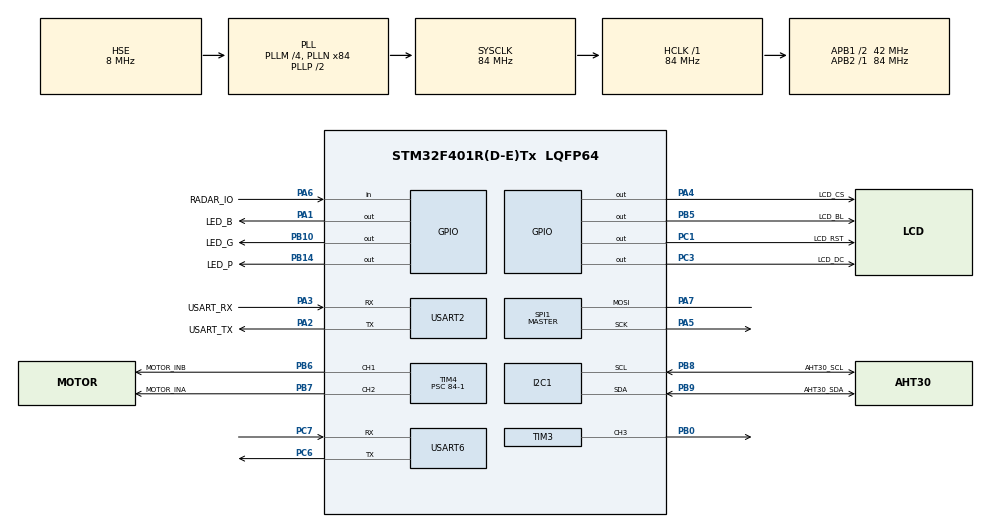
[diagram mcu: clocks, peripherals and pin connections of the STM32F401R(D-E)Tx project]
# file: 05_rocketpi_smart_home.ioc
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Dma.Request0=USART6_RX
Dma.Request1=USART6_TX
Dma.Request2=SPI1_TX
Dma.Request3=USART2_RX
Dma.Request4=USART2_TX
Dma.SPI1_TX.2.Direction=DMA_MEMORY_TO_PERIPH
Dma.SPI1_TX.2.FIFOMode=DMA_FIFOMODE_DISABLE
Dma.SPI1_TX.2.Instance=DMA2_Stream3
Dma.SPI1_TX.2.MemDataAlignment=DMA_MDATAALIGN_BYTE
Dma.SPI1_TX.2.MemInc=DMA_MINC_ENABLE
Dma.SPI1_TX.2.Mode=DMA_NORMAL
Dma.SPI1_TX.2.PeriphDataAlignment=DMA_PDATAALIGN_BYTE
Dma.SPI1_TX.2.PeriphInc=DMA_PINC_DISABLE
Dma.SPI1_TX.2.Priority=DMA_PRIORITY_LOW
Dma.USART2_RX.3.Direction=DMA_PERIPH_TO_MEMORY
Dma.USART2_RX.3.FIFOMode=DMA_FIFOMODE_DISABLE
Dma.USART2_RX.3.Instance=DMA1_Stream5
Dma.USART2_RX.3.MemDataAlignment=DMA_MDATAALIGN_BYTE
Dma.USART2_RX.3.MemInc=DMA_MINC_ENABLE
Dma.USART2_RX.3.Mode=DMA_NORMAL
Dma.USART2_RX.3.PeriphDataAlignment=DMA_PDATAALIGN_BYTE
Dma.USART2_RX.3.PeriphInc=DMA_PINC_DISABLE
Dma.USART2_RX.3.Priority=DMA_PRIORITY_LOW
Dma.USART2_TX.4.Direction=DMA_MEMORY_TO_PERIPH
Dma.USART2_TX.4.FIFOMode=DMA_FIFOMODE_DISABLE
Dma.USART2_TX.4.Instance=DMA1_Stream6
Dma.USART2_TX.4.MemDataAlignment=DMA_MDATAALIGN_BYTE
Dma.USART2_TX.4.MemInc=DMA_MINC_ENABLE
Dma.USART2_TX.4.Mode=DMA_NORMAL
Dma.USART2_TX.4.PeriphDataAlignment=DMA_PDATAALIGN_BYTE
Dma.USART2_TX.4.PeriphInc=DMA_PINC_DISABLE
Dma.USART2_TX.4.Priority=DMA_PRIORITY_LOW
Dma.USART6_RX.0.Direction=DMA_PERIPH_TO_MEMORY
Dma.USART6_RX.0.FIFOMode=DMA_FIFOMODE_DISABLE
Dma.USART6_RX.0.Instance=DMA2_Stream1
Dma.USART6_RX.0.MemDataAlignment=DMA_MDATAALIGN_BYTE
Dma.USART6_RX.0.MemInc=DMA_MINC_ENABLE
Dma.USART6_RX.0.Mode=DMA_NORMAL
Dma.USART6_RX.0.PeriphDataAlignment=DMA_PDATAALIGN_BYTE
Dma.USART6_RX.0.PeriphInc=DMA_PINC_DISABLE
Dma.USART6_RX.0.Priority=DMA_PRIORITY_LOW
Dma.USART6_TX.1.Direction=DMA_MEMORY_TO_PERIPH
Dma.USART6_TX.1.FIFOMode=DMA_FIFOMODE_DISABLE
Dma.USART6_TX.1.Instance=DMA2_Stream6
Dma.USART6_TX.1.MemDataAlignment=DMA_MDATAALIGN_BYTE
Dma.USART6_TX.1.MemInc=DMA_MINC_ENABLE
Dma.USART6_TX.1.Mode=DMA_NORMAL
Dma.USART6_TX.1.PeriphDataAlignment=DMA_PDATAALIGN_BYTE
Dma.USART6_TX.1.PeriphInc=DMA_PINC_DISABLE
Dma.USART6_TX.1.Priority=DMA_PRIORITY_LOW
Mcu.Family=STM32F4
Mcu.Name=STM32F401R(D-E)Tx
Mcu.Package=LQFP64
NVIC.DMA1_Stream5_IRQn=true\:0\:0\:false\:false\:true\:false\:true\:true
NVIC.DMA1_Stream6_IRQn=true\:0\:0\:false\:false\:true\:false\:true\:true
NVIC.DMA2_Stream1_IRQn=true\:0\:0\:false\:false\:true\:false\:true\:true
NVIC.DMA2_Stream3_IRQn=true\:0\:0\:false\:false\:true\:false\:true\:true
NVIC.DMA2_Stream6_IRQn=true\:0\:0\:false\:false\:true\:false\:true\:true
NVIC.PriorityGroup=NVIC_PRIORITYGROUP_4
NVIC.SPI1_IRQn=true\:0\:0\:false\:false\:true\:true\:true\:true
NVIC.USART2_IRQn=true\:0\:0\:false\:false\:true\:true\:true\:true
NVIC.USART6_IRQn=true\:0\:0\:false\:false\:true\:true\:true\:true
PA1.GPIO_Label=LED_B
PA1.Signal=GPIO_Output
PA13.GPIO_Label=TMS
PA13.Mode=Serial_Wire
PA13.Signal=SYS_JTMS-SWDIO
PA14.GPIO_Label=TCK
PA14.Mode=Serial_Wire
PA14.Signal=SYS_JTCK-SWCLK
PA2.GPIO_Label=USART_TX
PA2.GPIO_Mode=GPIO_MODE_AF_PP
PA2.GPIO_PuPd=GPIO_NOPULL
PA2.GPIO_Speed=GPIO_SPEED_FREQ_LOW
PA2.Mode=Asynchronous
PA2.Signal=USART2_TX
PA3.GPIO_Label=USART_RX
PA3.GPIO_Mode=GPIO_MODE_AF_PP
PA3.GPIO_PuPd=GPIO_NOPULL
PA3.GPIO_Speed=GPIO_SPEED_FREQ_LOW
PA3.Mode=Asynchronous
PA3.Signal=USART2_RX
PA4.GPIO_Label=LCD_CS
PA4.GPIO_Speed=GPIO_SPEED_FREQ_LOW
PA4.Signal=GPIO_Output
PA5.Mode=Simplex_Bidirectional_Master
PA5.Signal=SPI1_SCK
PA6.GPIO_Label=RADAR_IO
PA6.Signal=GPIO_Input
PA7.Mode=Simplex_Bidirectional_Master
PA7.Signal=SPI1_MOSI
PB0.Signal=S_TIM3_CH3
PB10.GPIO_Label=LED_G
PB10.Signal=GPIO_Output
PB14.GPIO_Label=LED_P
PB14.Signal=GPIO_Output
PB5.GPIO_Label=LCD_BL
PB5.Signal=GPIO_Output
PB6.GPIO_Label=MOTOR_INB
PB6.Signal=S_TIM4_CH1
PB7.GPIO_Label=MOTOR_INA
PB7.Signal=S_TIM4_CH2
PB8.GPIO_Label=AHT30_SCL
PB8.Mode=I2C
PB8.Signal=I2C1_SCL
PB9.GPIO_Label=AHT30_SDA
PB9.Mode=I2C
PB9.Signal=I2C1_SDA
PC1.GPIO_Label=LCD_RST
PC1.Signal=GPIO_Output
PC3.GPIO_Label=LCD_DC
PC3.Signal=GPIO_Output
PC6.Mode=Asynchronous
PC6.Signal=USART6_TX
PC7.Mode=Asynchronous
PC7.Signal=USART6_RX
PH0\ -\ OSC_IN.Mode=HSE-External-Oscillator
PH0\ -\ OSC_IN.Signal=RCC_OSC_IN
PH1\ -\ OSC_OUT.Mode=HSE-External-Oscillator
PH1\ -\ OSC_OUT.Signal=RCC_OSC_OUT
ProjectManager.HeapSize=0x4000
ProjectManager.StackSize=0x1000
ProjectManager.TargetToolchain=MDK-ARM V5.27
RCC.48MHZClocksFreq_Value=24000000
RCC.AHBFreq_Value=84000000
RCC.APB1CLKDivider=RCC_HCLK_DIV2
RCC.APB1Freq_Value=42000000
RCC.APB1TimFreq_Value=84000000
RCC.APB2Freq_Value=84000000
RCC.APB2TimFreq_Value=84000000
RCC.CortexFreq_Value=84000000
RCC.HCLKFreq_Value=84000000
RCC.HSE_VALUE=8000000
RCC.HSI_VALUE=16000000
RCC.LSE_VALUE=32768
RCC.PLLM=4
RCC.PLLN=84
RCC.PLLQ=7
RCC.PLLSourceVirtual=RCC_PLLSOURCE_HSE
RCC.SYSCLKFreq_VALUE=84000000
RCC.SYSCLKSource=RCC_SYSCLKSOURCE_PLLCLK
RCC.VCOOutputFreq_Value=168000000
SH.S_TIM3_CH3.0=TIM3_CH3,PWM Generation3 CH3
SH.S_TIM4_CH1.0=TIM4_CH1,PWM Generation1 CH1
SH.S_TIM4_CH2.0=TIM4_CH2,PWM Generation2 CH2
SPI1.Direction=SPI_DIRECTION_1LINE
SPI1.Mode=SPI_MODE_MASTER
SPI1.VirtualType=VM_MASTER
TIM3.Channel-PWM\ Generation3\ CH3=TIM_CHANNEL_3
TIM3.Period=369
TIM3.Prescaler=84-1
TIM3.Pulse-PWM\ Generation3\ CH3=185
TIM4.Channel-PWM\ Generation1\ CH1=TIM_CHANNEL_1
TIM4.Channel-PWM\ Generation2\ CH2=TIM_CHANNEL_2
TIM4.Period=50-1
TIM4.Prescaler=84-1
USART2.VirtualMode=VM_ASYNC
USART6.VirtualMode=VM_ASYNC
board=NUCLEO-F401RE

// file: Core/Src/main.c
/* USER CODE BEGIN Header */
/**
  ******************************************************************************
  * @file           : main.c
  * @brief          : Main program body
  ******************************************************************************
  * @attention
  *
  * Copyright (c) 2025 STMicroelectronics.
  * All rights reserved.
  *
  * This software is licensed under terms that can be found in the LICENSE file
  * in the root directory of this software component.
  * If no LICENSE file comes with this software, it is provided AS-IS.
  *
  ******************************************************************************
  */
/* USER CODE END Header */
#include "main.h"
#include "dma.h"
#include "i2c.h"
#include "spi.h"
#include "tim.h"
#include "usart.h"
#include "gpio.h"

/* USER CODE BEGIN Includes */
#include "app.h"
#include <stdio.h>
#include "font16x24_ascii.h"
/* USER CODE END Includes */

void SystemClock_Config(void);

int main(void)
{

  /* MCU Configuration--------------------------------------------------------*/

  /* Reset of all peripherals, Initializes the Flash interface and the Systick. */
  HAL_Init();

  /* Configure the system clock */
  SystemClock_Config();

  /* Initialize all configured peripherals */
  MX_GPIO_Init();
  MX_DMA_Init();
  MX_USART2_UART_Init();
  MX_USART6_UART_Init();
  MX_I2C1_Init();
  MX_TIM3_Init();
  MX_TIM4_Init();
  MX_SPI1_Init();
  /* USER CODE BEGIN 2 */
	HAL_Delay(500);

//	esp8266_at_test_run();
  App_Init();
  /* USER CODE END 2 */

  /* Infinite loop */
  /* USER CODE BEGIN WHILE */
  while (1)
  {
   App_Loop();
    /* USER CODE END WHILE */

  }
}

void SystemClock_Config(void)
{
  RCC_OscInitTypeDef RCC_OscInitStruct = {0};
  RCC_ClkInitTypeDef RCC_ClkInitStruct = {0};

  /** Configure the main internal regulator output voltage
  */
  __HAL_RCC_PWR_CLK_ENABLE();
  __HAL_PWR_VOLTAGESCALING_CONFIG(PWR_REGULATOR_VOLTAGE_SCALE2);

  /** Initializes the RCC Oscillators according to the specified parameters
  * in the RCC_OscInitTypeDef structure.
  */
  RCC_OscInitStruct.OscillatorType = RCC_OSCILLATORTYPE_HSE;
  RCC_OscInitStruct.HSEState = RCC_HSE_ON;
  RCC_OscInitStruct.PLL.PLLState = RCC_PLL_ON;
  RCC_OscInitStruct.PLL.PLLSource = RCC_PLLSOURCE_HSE;
  RCC_OscInitStruct.PLL.PLLM = 4;
  RCC_OscInitStruct.PLL.PLLN = 84;
  RCC_OscInitStruct.PLL.PLLP = RCC_PLLP_DIV2;
  RCC_OscInitStruct.PLL.PLLQ = 7;
  if (HAL_RCC_OscConfig(&RCC_OscInitStruct) != HAL_OK)
  {
    Error_Handler();
  }

  /** Initializes the CPU, AHB and APB buses clocks
  */
  RCC_ClkInitStruct.ClockType = RCC_CLOCKTYPE_HCLK|RCC_CLOCKTYPE_SYSCLK
                              |RCC_CLOCKTYPE_PCLK1|RCC_CLOCKTYPE_PCLK2;
  RCC_ClkInitStruct.SYSCLKSource = RCC_SYSCLKSOURCE_PLLCLK;
  RCC_ClkInitStruct.AHBCLKDivider = RCC_SYSCLK_DIV1;
  RCC_ClkInitStruct.APB1CLKDivider = RCC_HCLK_DIV2;
  RCC_ClkInitStruct.APB2CLKDivider = RCC_HCLK_DIV1;

  if (HAL_RCC_ClockConfig(&RCC_ClkInitStruct, FLASH_LATENCY_2) != HAL_OK)
  {
    Error_Handler();
  }
}

/* USER CODE BEGIN 4 */

/* 用于 Keil ARMCLANG，禁止半主机时需要提供 */
void _ttywrch(int ch)
{
    /* 根据需要发送到串口；如果不需要输出，留空即可 */
    (void)ch;
}

/* USER CODE END 4 */

void Error_Handler(void)
{
  __disable_irq();
  while (1)
  {
  }
}
